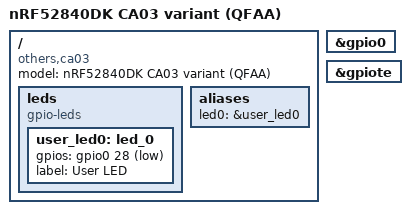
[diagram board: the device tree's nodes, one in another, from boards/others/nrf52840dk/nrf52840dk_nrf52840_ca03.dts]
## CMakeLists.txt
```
cmake_minimum_required(VERSION 3.20.0)

list(APPEND BOARD_ROOT ${CMAKE_CURRENT_SOURCE_DIR})

find_package(Zephyr REQUIRED HINTS $ENV{ZEPHYR_BASE})
project(nrf_blanktest)

target_sources(app PRIVATE src/main.c)
```

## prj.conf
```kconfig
CONFIG_GPIO=y

CONFIG_BT=y
CONFIG_BT_PERIPHERAL=y
CONFIG_BT_DEVICE_NAME="nRF_test"
CONFIG_BT_DEVICE_APPEARANCE=0
CONFIG_BT_MAX_CONN=1

CONFIG_SYSTEM_WORKQUEUE_STACK_SIZE=2048
CONFIG_MAIN_STACK_SIZE=2048
```

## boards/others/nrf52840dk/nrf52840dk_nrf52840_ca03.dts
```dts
/dts-v1/;
#include <zephyr/dt-bindings/gpio/gpio.h>
#include <nordic/nrf52840_qiaa.dtsi>

/ {
	model = "nRF52840DK CA03 variant (QFAA)";
	compatible = "others,ca03";

	leds {
		compatible = "gpio-leds";

		user_led0: led_0 {
			gpios = <&gpio0 28 GPIO_ACTIVE_LOW>;
			label = "User LED";
		};
	};

	aliases {
		led0 = &user_led0;
	};
};

&gpio0 {
	status = "okay";
};

&gpiote {
	status = "okay";
};
```

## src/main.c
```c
#include <zephyr/kernel.h>
#include <zephyr/bluetooth/bluetooth.h>
#include <zephyr/bluetooth/hci.h>
#include <hal/nrf_gpio.h>

static const struct bt_data ad[] = {
    BT_DATA_BYTES(BT_DATA_FLAGS, (BT_LE_AD_GENERAL | BT_LE_AD_NO_BREDR)),
    BT_DATA(BT_DATA_NAME_COMPLETE, CONFIG_BT_DEVICE_NAME, sizeof(CONFIG_BT_DEVICE_NAME) - 1),
};

int main(void)
{
    int err;

    /* 保留一个 LED 状态指示，P0.28 低亮高灭按你之前接法调整 */
    nrf_gpio_cfg_output(28);
    nrf_gpio_pin_set(28);   // 默认灭

    err = bt_enable(NULL);
    if (err) {
        /* BLE 初始化失败：快速闪烁 */
        while (1) {
            nrf_gpio_pin_clear(28);
            k_msleep(100);
            nrf_gpio_pin_set(28);
            k_msleep(100);
        }
    }

    err = bt_le_adv_start(BT_LE_ADV_CONN_FAST_1, ad, ARRAY_SIZE(ad), NULL, 0);
    if (err) {
        /* 广播启动失败：慢闪 */
        while (1) {
            nrf_gpio_pin_clear(28);
            k_msleep(500);
            nrf_gpio_pin_set(28);
            k_msleep(500);
        }
    }

    /* 广播成功：常亮 */
    nrf_gpio_pin_clear(28);

    while (1) {
        k_sleep(K_SECONDS(1));
    }
}
```
